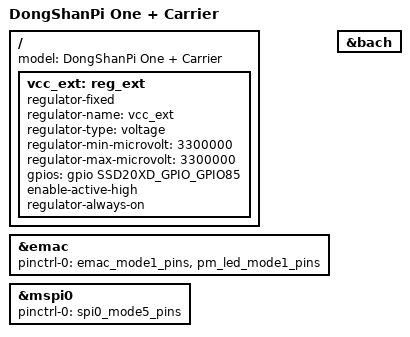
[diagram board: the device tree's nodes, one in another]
// SPDX-License-Identifier: GPL-2.0-or-later
/*
 * Copyright (c) 2021 thingy.jp.
 * Author: Daniel Palmer <daniel@thingy.jp>
 */

/dts-v1/;
#include "mstar-infinity2m-ssd202d-100ask-dongshanpione.dts"

#include <dt-bindings/gpio/gpio.h>

/ {
	model = "DongShanPi One + Carrier";

	vcc_ext: reg_ext  {
		compatible = "regulator-fixed";
		regulator-name = "vcc_ext";
		regulator-type = "voltage";
		regulator-min-microvolt = <3300000>;
		regulator-max-microvolt = <3300000>;
		gpios = <&gpio SSD20XD_GPIO_GPIO85 0>;
		enable-active-high;
		regulator-always-on;
	};
};


&emac {
	pinctrl-names = "default";
	pinctrl-0 = <&emac_mode1_pins>, <&pm_led_mode1_pins>;
	status = "okay";
};

&bach {
	status = "okay";
};

&mspi0 {
	pinctrl-names = "default";
	pinctrl-0 = <&spi0_mode5_pins>;
	status = "okay";
};
